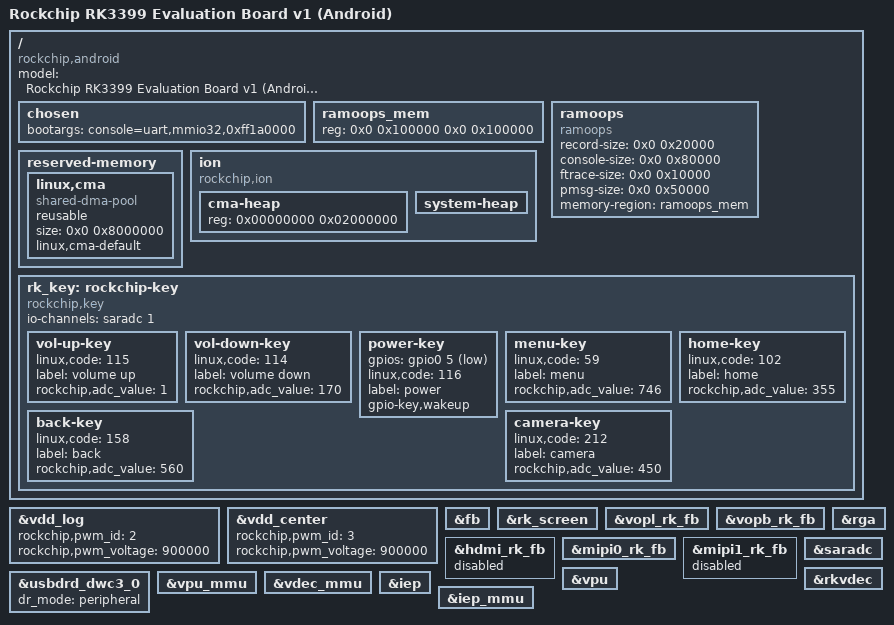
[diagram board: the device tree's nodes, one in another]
/*
 * Copyright (c) 2016 Fuzhou Rockchip Electronics Co., Ltd
 *
 * This file is dual-licensed: you can use it either under the terms
 * of the GPL or the X11 license, at your option. Note that this dual
 * licensing only applies to this file, and not this project as a
 * whole.
 *
 *  a) This file is free software; you can redistribute it and/or
 *     modify it under the terms of the GNU General Public License as
 *     published by the Free Software Foundation; either version 2 of the
 *     License, or (at your option) any later version.
 *
 *     This file is distributed in the hope that it will be useful,
 *     but WITHOUT ANY WARRANTY; without even the implied warranty of
 *     MERCHANTABILITY or FITNESS FOR A PARTICULAR PURPOSE.  See the
 *     GNU General Public License for more details.
 *
 * Or, alternatively,
 *
 *  b) Permission is hereby granted, free of charge, to any person
 *     obtaining a copy of this software and associated documentation
 *     files (the "Software"), to deal in the Software without
 *     restriction, including without limitation the rights to use,
 *     copy, modify, merge, publish, distribute, sublicense, and/or
 *     sell copies of the Software, and to permit persons to whom the
 *     Software is furnished to do so, subject to the following
 *     conditions:
 *
 *     The above copyright notice and this permission notice shall be
 *     included in all copies or substantial portions of the Software.
 *
 *     THE SOFTWARE IS PROVIDED "AS IS", WITHOUT WARRANTY OF ANY KIND,
 *     EXPRESS OR IMPLIED, INCLUDING BUT NOT LIMITED TO THE WARRANTIES
 *     OF MERCHANTABILITY, FITNESS FOR A PARTICULAR PURPOSE AND
 *     NONINFRINGEMENT. IN NO EVENT SHALL THE AUTHORS OR COPYRIGHT
 *     HOLDERS BE LIABLE FOR ANY CLAIM, DAMAGES OR OTHER LIABILITY,
 *     WHETHER IN AN ACTION OF CONTRACT, TORT OR OTHERWISE, ARISING
 *     FROM, OUT OF OR IN CONNECTION WITH THE SOFTWARE OR THE USE OR
 *     OTHER DEALINGS IN THE SOFTWARE.
 */

/dts-v1/;
#include "rk3399-evb.dtsi"
#include "rk3399-fb.dtsi"

/ {
	model = "Rockchip RK3399 Evaluation Board v1 (Android)";
	compatible = "rockchip,android", "rockchip,rk3399-evb1", "rockchip,rk3399";

	chosen {
		bootargs = "console=uart,mmio32,0xff1a0000";
	};

	ramoops_mem: ramoops_mem {
		reg = <0x0 0x100000 0x0 0x100000>;
		reg-names = "ramoops_mem";
	};

	ramoops {
		compatible = "ramoops";
		record-size = <0x0 0x20000>;
		console-size = <0x0 0x80000>;
		ftrace-size = <0x0 0x10000>;
		pmsg-size = <0x0 0x50000>;
		memory-region = <&ramoops_mem>;
	};

	reserved-memory {
		#address-cells = <2>;
		#size-cells = <2>;
		ranges;

		/* global autoconfigured region for contiguous allocations */
		linux,cma {
			compatible = "shared-dma-pool";
			reusable;
			size = <0x0 0x8000000>;
			linux,cma-default;
		};
	};

	ion {
		compatible = "rockchip,ion";
		#address-cells = <1>;
		#size-cells = <0>;

		cma-heap {
			reg = <0x00000000 0x02000000>;
		};

		system-heap {
		};
	};

	rk_key: rockchip-key {
		compatible = "rockchip,key";
		status = "okay";

		io-channels = <&saradc 1>;

		vol-up-key {
			linux,code = <115>;
			label = "volume up";
			rockchip,adc_value = <1>;
		};

		vol-down-key {
			linux,code = <114>;
			label = "volume down";
			rockchip,adc_value = <170>;
		};

		power-key {
			gpios = <&gpio0 5 GPIO_ACTIVE_LOW>;
			linux,code = <116>;
			label = "power";
			gpio-key,wakeup;
		};

		menu-key {
			linux,code = <59>;
			label = "menu";
			rockchip,adc_value = <746>;
		};

		home-key {
			linux,code = <102>;
			label = "home";
			rockchip,adc_value = <355>;
		};

		back-key {
			linux,code = <158>;
			label = "back";
			rockchip,adc_value = <560>;
		};

		camera-key {
			linux,code = <212>;
			label = "camera";
			rockchip,adc_value = <450>;
		};
	};
};

&vdd_log {
	rockchip,pwm_id= <2>;
	rockchip,pwm_voltage = <900000>;
};

&vdd_center {
	rockchip,pwm_id= <3>;
	rockchip,pwm_voltage = <900000>;
};

&fb {
	status = "okay";
};

&rk_screen {
	status = "okay";
	#include <dt-bindings/display/screen-timing/lcd-tv080wum-nl0-mipi.dtsi>
};

&vopl_rk_fb {
	status = "okay";
};

&vopb_rk_fb {
	status = "okay";
};

&rga {
	status = "okay";
};

&hdmi_rk_fb {
	status = "disabled";
};

&mipi0_rk_fb {
	status = "okay";
};

&mipi1_rk_fb{
	status = "disabled";
};

&saradc {
	status = "okay";
};

&usbdrd_dwc3_0 {
	dr_mode = "peripheral";
};

&vpu {
	status = "okay";
};

&rkvdec {
	status = "okay";
};

&vpu_mmu {
	status = "okay";
};

&vdec_mmu {
	status = "okay";
};

&iep {
	status = "okay";
};

&iep_mmu {
	status = "okay";
};
